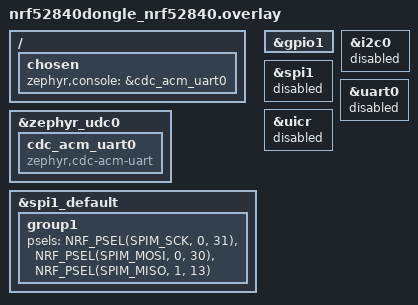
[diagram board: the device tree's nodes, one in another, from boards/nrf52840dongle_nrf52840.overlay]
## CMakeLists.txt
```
#
# Copyright (c) 2018 Nordic Semiconductor
#
# SPDX-License-Identifier: LicenseRef-Nordic-5-Clause
#
cmake_minimum_required(VERSION 3.20.0)

find_package(Zephyr REQUIRED HINTS $ENV{ZEPHYR_BASE})
project(NONE)

# NORDIC SDK APP START
target_sources(app PRIVATE
  src/main.c
  src/my_lbs.c
)

# NORDIC SDK APP END
zephyr_library_include_directories(.)
```

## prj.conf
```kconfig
#
# 10.12.2023r
# Projekt na pracę dyplomową "Konwerter energii cieplnej ciała ludzkiego do zasilania elementów IoT"
# Wiktor Pantak
# Akademia Górniczo-Hutnicza im. Stanisława Staszica w Krakowie
# AGH University in Cracov
# Plik konfiguracyjny
#

# Logger module
CONFIG_LOG=y

# Bluetooth LE
CONFIG_BT=y
CONFIG_BT_PERIPHERAL=y
CONFIG_BT_DEVICE_NAME="NRF_Prototype"

# GPIO
CONFIG_GPIO=y
CONFIG_GPIO_NRFX=y
CONFIG_GPIO_NRFX_INTERRUPT=y
CONFIG_GPIO_AS_PINRESET=y

# Increase stack size for the main thread and System Workqueue
CONFIG_SYSTEM_WORKQUEUE_STACK_SIZE=2048
CONFIG_MAIN_STACK_SIZE=2048
```

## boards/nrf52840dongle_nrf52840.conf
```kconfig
# USB stack and CDC ACM settings
CONFIG_USB_DEVICE_STACK=y
CONFIG_USB_DEVICE_REMOTE_WAKEUP=n
CONFIG_USB_CDC_ACM=y
CONFIG_USB_DEVICE_MANUFACTURER="Nordic Semiconductor ASA"
CONFIG_USB_DEVICE_PRODUCT="nRF52840 Dongle"
CONFIG_USB_DEVICE_VID=0x1915
CONFIG_USB_DEVICE_PID=0x0001
CONFIG_USB_DEVICE_INITIALIZE_AT_BOOT=y
CONFIG_USB_DEVICE_LOG_LEVEL_OFF=y
CONFIG_USB_CDC_ACM_LOG_LEVEL_OFF=y
CONFIG_USB_CDC_ACM_RINGBUF_SIZE=2048

# Console settings
CONFIG_CONSOLE=y
CONFIG_SERIAL=y
CONFIG_UART_CONSOLE=y
CONFIG_UART_INTERRUPT_DRIVEN=y

# Logger settings
CONFIG_LOG=y
CONFIG_LOG_BACKEND_UART=y
CONFIG_LOG_MODE_DEFERRED=y
```

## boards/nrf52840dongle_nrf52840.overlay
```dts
/*
 * Copyright (c) 2021 Nordic Semiconductor ASA
 *
 * SPDX-License-Identifier: LicenseRef-Nordic-5-Clause
 */

/ {
	chosen {
		zephyr,console = &cdc_acm_uart0;
	};
};

&zephyr_udc0 {
	cdc_acm_uart0: cdc_acm_uart0 {
		compatible = "zephyr,cdc-acm-uart";
	};
};

&spi1_default {
	group1 {
		psels = <NRF_PSEL(SPIM_SCK, 0, 31)>,
		  <NRF_PSEL(SPIM_MOSI, 0, 30)>,
		  <NRF_PSEL(SPIM_MISO, 1, 13)>;
	};
};

&gpio1 {
	status = "okay";
};

&i2c0 {
	status = "disabled";
};

&spi1 {
	status = "disabled";
};

&uart0 {
	status = "disabled";
};

&uicr {
	status = "disabled";
};
```

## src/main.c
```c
/*
10.12.2023r
Projekt na pracę dyplomową "Konwerter energii cieplnej ciała ludzkiego do zasilania elementów IoT"
Wiktor Pantak
Akademia Górniczo-Hutnicza im. Stanisława Staszica w Krakowie
AGH University in Cracov
Projekt wykorzystujący nrf52840-dongle do przedstawienia możliwości wykorzystania ciepła
ciała ludzkiego do zasilania elementów IoT.
Mikrokontroler wysyła co pewien czas ustawiany parametrem NOTIFY_INTERVAL
dane typu uint32 do klienta (peera).
*/

#include <zephyr/kernel.h>
#include <zephyr/logging/log.h>
#include <zephyr/bluetooth/bluetooth.h>
#include <zephyr/bluetooth/gap.h>
#include <zephyr/bluetooth/uuid.h>
#include <zephyr/bluetooth/conn.h>
#include <zephyr/drivers/gpio.h>
#include <zephyr/device.h>
#include "my_lbs.h"

static struct bt_le_adv_param *adv_param = BT_LE_ADV_PARAM(
	(BT_LE_ADV_OPT_CONNECTABLE |
	 BT_LE_ADV_OPT_USE_IDENTITY), /* Connectable advertising and use identity address */
	800, /* Min Advertising Interval 500ms (800*0.625ms) */
	801, /* Max Advertising Interval 500.625ms (801*0.625ms) */
	NULL); /* Set to NULL for undirected advertising */

LOG_MODULE_REGISTER(Lesson4_Exercise2, LOG_LEVEL_INF);

#define DEVICE_NAME CONFIG_BT_DEVICE_NAME
#define DEVICE_NAME_LEN (sizeof(DEVICE_NAME) - 1)

#define STACKSIZE 1024
#define PRIORITY 7

//okres wysyłania danych w miliseknudach
#define NOTIFY_INTERVAL         30000

/* Definicje pinów i konfiguracja flag dla przerwania */
#define PIN 13
#define EDGE GPIO_INT_LEVEL_HIGH
#define BUTTON_PIN (DT_ALIAS_SW0_GPIOS_PIN)

static uint32_t app_sensor_value = 100;

static const struct device *gpio_ct_dev = DEVICE_DT_GET(DT_N_NODELABEL_gpio1);


static const struct bt_data ad[] = {
	BT_DATA_BYTES(BT_DATA_FLAGS, (BT_LE_AD_GENERAL | BT_LE_AD_NO_BREDR)),
	BT_DATA(BT_DATA_NAME_COMPLETE, DEVICE_NAME, DEVICE_NAME_LEN),

};

static const struct bt_data sd[] = {
	BT_DATA_BYTES(BT_DATA_UUID128_ALL, BT_UUID_LBS_VAL),
};

//wysyłane dane
static void simulate_data(void)
{
	app_sensor_value++;
	if (app_sensor_value == 200) {
		app_sensor_value = 100;
	}
}
//wysyłanie danych
// void send_data_timer_handler(struct k_timer *timer_id) 
// {         
//     simulate_data();
//     my_lbs_send_sensor_notify(app_sensor_value);
// }
// K_TIMER_DEFINE(send_data_timer, send_data_timer_handler, NULL);

//wysyłanie danych
// void send_data_thread(void)
// {
// 	while(1){
// 		/* Simulate data */
// 		simulate_data();
// 		/* Send notification, the function sends notifications only if a client is subscribed */
// 		my_lbs_send_sensor_notify(app_sensor_value);

// 		k_sleep(K_MSEC(NOTIFY_INTERVAL));
// 	}
// }

/* Funkcja obsługująca przerwanie */
void button_pressed(struct device *gpiob, struct gpio_callback *cb,
                    uint32_t pins)
{
    simulate_data();
    my_lbs_send_sensor_notify(app_sensor_value);
}

static void on_connected(struct bt_conn *conn, uint8_t err)
{
	if (err) {
		printk("Connection failed (err %u)\n", err);
		return;
	}

	printk("Connected\n");

}

static void on_disconnected(struct bt_conn *conn, uint8_t reason)
{
	printk("Disconnected (reason %u)\n", reason);

}

struct bt_conn_cb connection_callbacks = {
	.connected = on_connected,
	.disconnected = on_disconnected,
};

void main(void)
{
	int err;

	err = bt_enable(NULL);
	if (err) {
		LOG_ERR("Bluetooth init failed (err %d)\n", err);
		return;
	}
	//uruchomienie modułu bluetooth
	bt_conn_cb_register(&connection_callbacks);

	LOG_INF("Bluetooth initialized\n");
	err = bt_le_adv_start(adv_param, ad, ARRAY_SIZE(ad), sd, ARRAY_SIZE(sd));
	if (err) {
		LOG_ERR("Advertising failed to start (err %d)\n", err);
		return;
	}

	LOG_INF("Advertising successfully started\n");
	//uruchomienie licznika czasu
	//k_timer_start(&send_data_timer, K_MSEC(NOTIFY_INTERVAL), K_MSEC(NOTIFY_INTERVAL));
	
    struct gpio_callback button_cb;

    /* Inicjalizacja pinu jako wejście z rezystorem podciągającym */
	if(!device_is_ready(gpio_ct_dev)){
		return;
	}

	err = gpio_pin_configure(gpio_ct_dev, 13, GPIO_INPUT | GPIO_PULL_UP);
	if(err != 0){
		return;
	}

	/* Konfiguracja przerwań na pinie */
    gpio_pin_interrupt_configure(gpio_ct_dev, 13, EDGE);

    /* Konfiguracja funkcji obsługującej przerwanie */
    gpio_init_callback(&button_cb, button_pressed, BIT(13));
    gpio_add_callback(gpio_ct_dev, &button_cb);


	while(1){
		k_sleep(K_FOREVER);
	}
	return;
}
//uruchomienie wątku wysyłania danych przez BLE
// K_THREAD_DEFINE(send_data_thread_id, STACKSIZE, send_data_thread, NULL, NULL, NULL, PRIORITY, 0, 0);
```

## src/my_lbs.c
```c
/*
10.12.2023r
Projekt na pracę dyplomową "Konwerter energii cieplnej ciała ludzkiego do zasilania elementów IoT"
Wiktor Pantak
Akademia Górniczo-Hutnicza im. Stanisława Staszica w Krakowie
AGH University in Cracov
*/

#include <zephyr/types.h>
#include <stddef.h>
#include <string.h>
#include <errno.h>
#include <zephyr/sys/printk.h>
#include <zephyr/sys/byteorder.h>
#include <zephyr/kernel.h>
#include <zephyr/logging/log.h>
#include <zephyr/bluetooth/bluetooth.h>
#include <zephyr/bluetooth/hci.h>
#include <zephyr/bluetooth/conn.h>
#include <zephyr/bluetooth/uuid.h>
#include <zephyr/bluetooth/gatt.h>

#include "my_lbs.h"

LOG_MODULE_DECLARE(Lesson4_Exercise2);

static bool notify_mysensor_enabled;

//funkcja ustawiająca zmienną, czy klient chce otrzymywać dane z serwera
static void mylbsbc_ccc_mysensor_cfg_changed(const struct bt_gatt_attr *attr, uint16_t value)
{
	notify_mysensor_enabled = (value == BT_GATT_CCC_NOTIFY);
}

/* Number Sending Service Declaration */
BT_GATT_SERVICE_DEFINE(
	my_lbs_svc, BT_GATT_PRIMARY_SERVICE(BT_UUID_LBS),
	BT_GATT_CHARACTERISTIC(BT_UUID_LBS_MYSENSOR,
			       BT_GATT_CHRC_NOTIFY,
			       BT_GATT_PERM_NONE, NULL, NULL,
			       NULL),
	BT_GATT_CCC(mylbsbc_ccc_mysensor_cfg_changed,
		    BT_GATT_PERM_READ | BT_GATT_PERM_WRITE),
);

//wysyłanie danych, gdy notify_mysensor_enabled == true
int my_lbs_send_sensor_notify(uint32_t sensor_value)
{
	if (!notify_mysensor_enabled) {
		return -EACCES;
	}

	return bt_gatt_notify(NULL, &my_lbs_svc.attrs[2], 
			      &sensor_value,
			      sizeof(sensor_value));
}
```

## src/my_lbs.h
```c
/*
10.12.2023r
Projekt na pracę dyplomową "Konwerter energii cieplnej ciała ludzkiego do zasilania elementów IoT"
Wiktor Pantak
Akademia Górniczo-Hutnicza im. Stanisława Staszica w Krakowie
AGH University in Cracov

Deinicja serwisów dla aplikacji NRF CONNECT FOR MOBILE
oraz funkcji wysyłania danych do klientów (peerów).
*/

#ifndef BT_LBS_H_
#define BT_LBS_H_

#ifdef __cplusplus
extern "C" {
#endif

#include <zephyr/types.h>

/** @brief LBS Service UUID. */
#define BT_UUID_LBS_VAL BT_UUID_128_ENCODE(0x00001523, 0x1212, 0xefde, 0x1523, 0x785feabcd123)
#define BT_UUID_LBS_MYSENSOR_VAL BT_UUID_128_ENCODE(0x00001526, 0x1212, 0xefde, 0x1523, 0x785feabcd123)

#define BT_UUID_LBS BT_UUID_DECLARE_128(BT_UUID_LBS_VAL)
#define BT_UUID_LBS_MYSENSOR       BT_UUID_DECLARE_128(BT_UUID_LBS_MYSENSOR_VAL)


/** @brief Send the sensor value as notification.
 *
 * This function sends an uint32_t  value, typically the value
 * of a simulated sensor to all connected peers.
 *
 * @param[in] sensor_value The value of the simulated sensor.
 *
 * @retval 0 If the operation was successful.
 *           Otherwise, a (negative) error code is returned.
 */
int my_lbs_send_sensor_notify(uint32_t sensor_value);

#ifdef __cplusplus
}
#endif

#endif /* BT_LBS_H_ */
```
